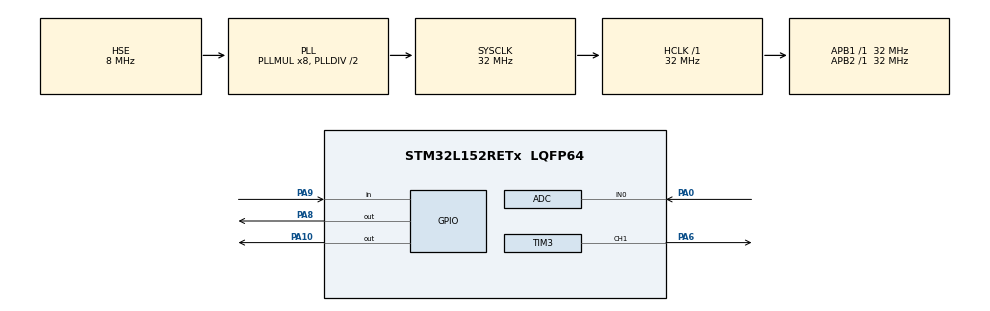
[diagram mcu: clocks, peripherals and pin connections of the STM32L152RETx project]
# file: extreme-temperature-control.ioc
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ADC.Channel-0\#ChannelRegularConversion=ADC_CHANNEL_0
ADC.ContinuousConvMode=ENABLE
ADC.NbrOfConversionFlag=1
ADC.Rank-0\#ChannelRegularConversion=1
ADC.SamplingTime-0\#ChannelRegularConversion=ADC_SAMPLETIME_384CYCLES
FREERTOS.Tasks01=defaultTask,24,128,StartDefaultTask,Default,NULL,Dynamic,NULL,NULL
FREERTOS.configUSE_NEWLIB_REENTRANT=1
Mcu.Family=STM32L1
Mcu.Name=STM32L152RETx
Mcu.Package=LQFP64
NVIC.ADC1_IRQn=true\:5\:0\:false\:false\:true\:true\:true\:true\:true
NVIC.PriorityGroup=NVIC_PRIORITYGROUP_4
NVIC.TIM2_IRQn=true\:5\:0\:false\:false\:true\:true\:true\:true\:true
NVIC.TIM6_IRQn=true\:15\:0\:false\:false\:true\:false\:false\:true\:true
NVIC.TimeBase=TIM6_IRQn
NVIC.TimeBaseIP=TIM6
PA0-WKUP1.Mode=IN0
PA0-WKUP1.Signal=ADC_IN0
PA10.Signal=GPIO_Output
PA13.Mode=Serial_Wire
PA13.Signal=SYS_JTMS-SWDIO
PA14.Mode=Serial_Wire
PA14.Signal=SYS_JTCK-SWCLK
PA6.Signal=S_TIM3_CH1
PA8.Signal=GPIO_Output
PA9.Signal=GPIO_Input
PH0-OSC_IN.Mode=HSE-External-Oscillator
PH0-OSC_IN.Signal=RCC_OSC_IN
PH1-OSC_OUT.Mode=HSE-External-Oscillator
PH1-OSC_OUT.Signal=RCC_OSC_OUT
ProjectManager.HeapSize=0x200
ProjectManager.StackSize=0x400
ProjectManager.TargetToolchain=STM32CubeIDE
RCC.48MHZClocksFreq_Value=32000000
RCC.AHBFreq_Value=32000000
RCC.APB1Freq_Value=32000000
RCC.APB1TimFreq_Value=32000000
RCC.APB2Freq_Value=32000000
RCC.APB2TimFreq_Value=32000000
RCC.HCLKFreq_Value=32000000
RCC.HSE_VALUE=8000000
RCC.HSI_VALUE=16000000
RCC.LSE_VALUE=32768
RCC.MSI_VALUE=2097000
RCC.PLLMUL=RCC_PLL_MUL8
RCC.PLLSourceVirtual=RCC_PLLSOURCE_HSE
RCC.RTCClockSelectionVirtual=RCC_RTCCLKSOURCE_LSE
RCC.SYSCLKFreq_VALUE=32000000
RCC.SYSCLKSource=RCC_SYSCLKSOURCE_PLLCLK
RCC.USBOutput=48000000
RCC.VCOOutputFreq_Value=64000000
SH.S_TIM3_CH1.0=TIM3_CH1,PWM Generation1 CH1
TIM2.Period=0xFFFF -1
TIM2.Prescaler=31
TIM3.Channel-PWM\ Generation1\ CH1=TIM_CHANNEL_1
TIM3.Period=2000
TIM3.Prescaler=1
VP_FREERTOS_VS_CMSIS_V2.Mode=CMSIS_V2
VP_SYS_VS_tim6.Mode=TIM6
VP_TIM2_VS_ClockSourceINT.Mode=Internal
VP_TIM3_VS_ClockSourceINT.Mode=Internal
board=NUCLEO-L152RE

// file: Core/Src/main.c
/* USER CODE BEGIN Header */
/**
  ******************************************************************************
  * @file           : main.c
  * @brief          : Main program body
  ******************************************************************************
  * @attention
  *
  * Copyright (c) 2024 STMicroelectronics.
  * All rights reserved.
  *
  * This software is licensed under terms that can be found in the LICENSE file
  * in the root directory of this software component.
  * If no LICENSE file comes with this software, it is provided AS-IS.
  *
  ******************************************************************************
  */
/* USER CODE END Header */
#include "main.h"
#include "cmsis_os.h"

ADC_HandleTypeDef hadc;

TIM_HandleTypeDef htim2;
TIM_HandleTypeDef htim3;

/* Definitions for defaultTask */
osThreadId_t defaultTaskHandle;
const osThreadAttr_t defaultTask_attributes = {
  .name = "defaultTask",
  .stack_size = 128 * 4,
  .priority = (osPriority_t) osPriorityNormal,
};

void SystemClock_Config(void);
static void MX_GPIO_Init(void);
static void MX_ADC_Init(void);
static void MX_TIM2_Init(void);
static void MX_TIM3_Init(void);
void StartDefaultTask(void *argument);

int main(void)
{

  /* MCU Configuration--------------------------------------------------------*/

  /* Reset of all peripherals, Initializes the Flash interface and the Systick. */
  HAL_Init();

  /* Configure the system clock */
  SystemClock_Config();

  /* Initialize all configured peripherals */
  MX_GPIO_Init();
  MX_ADC_Init();
  MX_TIM2_Init();
  MX_TIM3_Init();
  /* USER CODE BEGIN 2 */
	init_temperature_sensor(&hadc);
	init_distance_sensor(&htim2);
	init_led();
	init_alarm();
  /* USER CODE END 2 */

  /* Init scheduler */
  osKernelInitialize();

  /* USER CODE BEGIN RTOS_SEMAPHORES */
  /* add semaphores, ... */
 distance_mutex = xSemaphoreCreateMutex();
 temperature_mutex = xSemaphoreCreateMutex();
 temperature_t_mutex = xSemaphoreCreateMutex();

  /* USER CODE END RTOS_SEMAPHORES */

  /* Create the thread(s) */
  /* creation of defaultTask */
  defaultTaskHandle = osThreadNew(StartDefaultTask, NULL, &defaultTask_attributes);

  /* USER CODE BEGIN RTOS_THREADS */
  /* add threads, ... */
create_tasks();
  /* USER CODE END RTOS_THREADS */

  /* Start scheduler */
  osKernelStart();

  /* We should never get here as control is now taken by the scheduler */
  /* Infinite loop */
  while (1)
  {
  }
}

void SystemClock_Config(void)
{
  RCC_OscInitTypeDef RCC_OscInitStruct = {0};
  RCC_ClkInitTypeDef RCC_ClkInitStruct = {0};

  /** Configure the main internal regulator output voltage
  */
  __HAL_PWR_VOLTAGESCALING_CONFIG(PWR_REGULATOR_VOLTAGE_SCALE1);

  /** Initializes the RCC Oscillators according to the specified parameters
  * in the RCC_OscInitTypeDef structure.
  */
  RCC_OscInitStruct.OscillatorType = RCC_OSCILLATORTYPE_HSI|RCC_OSCILLATORTYPE_HSE;
  RCC_OscInitStruct.HSEState = RCC_HSE_ON;
  RCC_OscInitStruct.HSIState = RCC_HSI_ON;
  RCC_OscInitStruct.HSICalibrationValue = RCC_HSICALIBRATION_DEFAULT;
  RCC_OscInitStruct.PLL.PLLState = RCC_PLL_ON;
  RCC_OscInitStruct.PLL.PLLSource = RCC_PLLSOURCE_HSE;
  RCC_OscInitStruct.PLL.PLLMUL = RCC_PLL_MUL8;
  RCC_OscInitStruct.PLL.PLLDIV = RCC_PLL_DIV2;
  if (HAL_RCC_OscConfig(&RCC_OscInitStruct) != HAL_OK)
  {
    Error_Handler();
  }

  /** Initializes the CPU, AHB and APB buses clocks
  */
  RCC_ClkInitStruct.ClockType = RCC_CLOCKTYPE_HCLK|RCC_CLOCKTYPE_SYSCLK
                              |RCC_CLOCKTYPE_PCLK1|RCC_CLOCKTYPE_PCLK2;
  RCC_ClkInitStruct.SYSCLKSource = RCC_SYSCLKSOURCE_PLLCLK;
  RCC_ClkInitStruct.AHBCLKDivider = RCC_SYSCLK_DIV1;
  RCC_ClkInitStruct.APB1CLKDivider = RCC_HCLK_DIV1;
  RCC_ClkInitStruct.APB2CLKDivider = RCC_HCLK_DIV1;

  if (HAL_RCC_ClockConfig(&RCC_ClkInitStruct, FLASH_LATENCY_1) != HAL_OK)
  {
    Error_Handler();
  }
}

static void MX_ADC_Init(void)
{

  ADC_ChannelConfTypeDef sConfig = {0};

  /** Configure the global features of the ADC (Clock, Resolution, Data Alignment and number of conversion)
  */
  hadc.Instance = ADC1;
  hadc.Init.ClockPrescaler = ADC_CLOCK_ASYNC_DIV1;
  hadc.Init.Resolution = ADC_RESOLUTION_12B;
  hadc.Init.DataAlign = ADC_DATAALIGN_RIGHT;
  hadc.Init.ScanConvMode = ADC_SCAN_DISABLE;
  hadc.Init.EOCSelection = ADC_EOC_SEQ_CONV;
  hadc.Init.LowPowerAutoWait = ADC_AUTOWAIT_DISABLE;
  hadc.Init.LowPowerAutoPowerOff = ADC_AUTOPOWEROFF_DISABLE;
  hadc.Init.ChannelsBank = ADC_CHANNELS_BANK_A;
  hadc.Init.ContinuousConvMode = ENABLE;
  hadc.Init.NbrOfConversion = 1;
  hadc.Init.DiscontinuousConvMode = DISABLE;
  hadc.Init.ExternalTrigConv = ADC_SOFTWARE_START;
  hadc.Init.ExternalTrigConvEdge = ADC_EXTERNALTRIGCONVEDGE_NONE;
  hadc.Init.DMAContinuousRequests = DISABLE;
  if (HAL_ADC_Init(&hadc) != HAL_OK)
  {
    Error_Handler();
  }

  /** Configure for the selected ADC regular channel its corresponding rank in the sequencer and its sample time.
  */
  sConfig.Channel = ADC_CHANNEL_0;
  sConfig.Rank = ADC_REGULAR_RANK_1;
  sConfig.SamplingTime = ADC_SAMPLETIME_384CYCLES;
  if (HAL_ADC_ConfigChannel(&hadc, &sConfig) != HAL_OK)
  {
    Error_Handler();
  }

}

static void MX_TIM2_Init(void)
{

  TIM_ClockConfigTypeDef sClockSourceConfig = {0};
  TIM_MasterConfigTypeDef sMasterConfig = {0};

  htim2.Instance = TIM2;
  htim2.Init.Prescaler = 31;
  htim2.Init.CounterMode = TIM_COUNTERMODE_UP;
  htim2.Init.Period = 0xFFFF -1;
  htim2.Init.ClockDivision = TIM_CLOCKDIVISION_DIV1;
  htim2.Init.AutoReloadPreload = TIM_AUTORELOAD_PRELOAD_DISABLE;
  if (HAL_TIM_Base_Init(&htim2) != HAL_OK)
  {
    Error_Handler();
  }
  sClockSourceConfig.ClockSource = TIM_CLOCKSOURCE_INTERNAL;
  if (HAL_TIM_ConfigClockSource(&htim2, &sClockSourceConfig) != HAL_OK)
  {
    Error_Handler();
  }
  sMasterConfig.MasterOutputTrigger = TIM_TRGO_RESET;
  sMasterConfig.MasterSlaveMode = TIM_MASTERSLAVEMODE_DISABLE;
  if (HAL_TIMEx_MasterConfigSynchronization(&htim2, &sMasterConfig) != HAL_OK)
  {
    Error_Handler();
  }

}

static void MX_TIM3_Init(void)
{

  TIM_ClockConfigTypeDef sClockSourceConfig = {0};
  TIM_MasterConfigTypeDef sMasterConfig = {0};
  TIM_OC_InitTypeDef sConfigOC = {0};

  htim3.Instance = TIM3;
  htim3.Init.Prescaler = 1;
  htim3.Init.CounterMode = TIM_COUNTERMODE_UP;
  htim3.Init.Period = 2000;
  htim3.Init.ClockDivision = TIM_CLOCKDIVISION_DIV1;
  htim3.Init.AutoReloadPreload = TIM_AUTORELOAD_PRELOAD_DISABLE;
  if (HAL_TIM_Base_Init(&htim3) != HAL_OK)
  {
    Error_Handler();
  }
  sClockSourceConfig.ClockSource = TIM_CLOCKSOURCE_INTERNAL;
  if (HAL_TIM_ConfigClockSource(&htim3, &sClockSourceConfig) != HAL_OK)
  {
    Error_Handler();
  }
  if (HAL_TIM_PWM_Init(&htim3) != HAL_OK)
  {
    Error_Handler();
  }
  sMasterConfig.MasterOutputTrigger = TIM_TRGO_RESET;
  sMasterConfig.MasterSlaveMode = TIM_MASTERSLAVEMODE_DISABLE;
  if (HAL_TIMEx_MasterConfigSynchronization(&htim3, &sMasterConfig) != HAL_OK)
  {
    Error_Handler();
  }
  sConfigOC.OCMode = TIM_OCMODE_PWM1;
  sConfigOC.Pulse = 0;
  sConfigOC.OCPolarity = TIM_OCPOLARITY_HIGH;
  sConfigOC.OCFastMode = TIM_OCFAST_DISABLE;
  if (HAL_TIM_PWM_ConfigChannel(&htim3, &sConfigOC, TIM_CHANNEL_1) != HAL_OK)
  {
    Error_Handler();
  }
  HAL_TIM_MspPostInit(&htim3);

}

static void MX_GPIO_Init(void)
{
  GPIO_InitTypeDef GPIO_InitStruct = {0};

  /* GPIO Ports Clock Enable */
  __HAL_RCC_GPIOH_CLK_ENABLE();
  __HAL_RCC_GPIOA_CLK_ENABLE();

  /*Configure GPIO pin Output Level */
  HAL_GPIO_WritePin(GPIOA, GPIO_PIN_8|GPIO_PIN_10, GPIO_PIN_RESET);

  /*Configure GPIO pins : PA8 PA10 */
  GPIO_InitStruct.Pin = GPIO_PIN_8|GPIO_PIN_10;
  GPIO_InitStruct.Mode = GPIO_MODE_OUTPUT_PP;
  GPIO_InitStruct.Pull = GPIO_NOPULL;
  GPIO_InitStruct.Speed = GPIO_SPEED_FREQ_LOW;
  HAL_GPIO_Init(GPIOA, &GPIO_InitStruct);

  /*Configure GPIO pin : PA9 */
  GPIO_InitStruct.Pin = GPIO_PIN_9;
  GPIO_InitStruct.Mode = GPIO_MODE_INPUT;
  GPIO_InitStruct.Pull = GPIO_NOPULL;
  HAL_GPIO_Init(GPIOA, &GPIO_InitStruct);

}

void StartDefaultTask(void *argument)
{
  for(;;)
  {
    osDelay(1);
  }
}

void HAL_TIM_PeriodElapsedCallback(TIM_HandleTypeDef *htim)
{
  if (htim->Instance == TIM6) {
    HAL_IncTick();
  }
}

void Error_Handler(void)
{
  __disable_irq();
  while (1)
  {
  }
}
